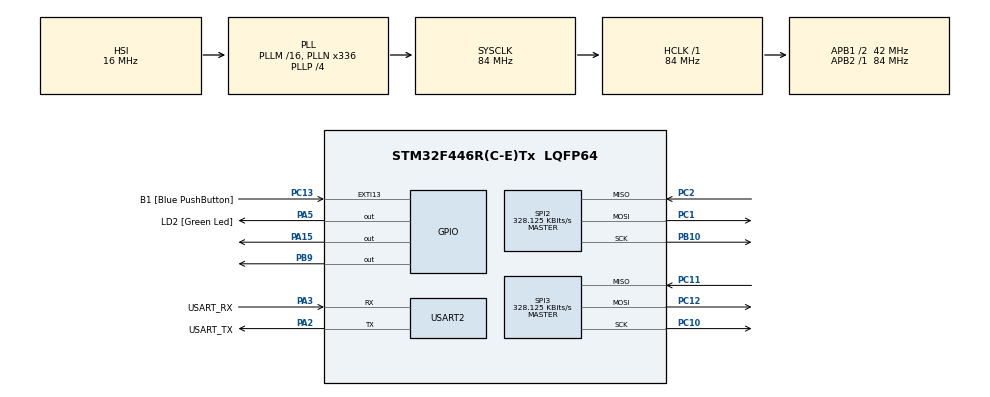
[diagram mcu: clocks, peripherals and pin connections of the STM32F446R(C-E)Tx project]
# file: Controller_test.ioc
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Mcu.Family=STM32F4
Mcu.Name=STM32F446R(C-E)Tx
Mcu.Package=LQFP64
NVIC.PriorityGroup=NVIC_PRIORITYGROUP_0
NVIC.TIM6_DAC_IRQn=true\:0\:0\:false\:false\:true\:true
PA13.GPIO_Label=TMS
PA13.Mode=Serial_Wire
PA13.Signal=SYS_JTMS-SWDIO
PA14.GPIO_Label=TCK
PA14.Mode=Serial_Wire
PA14.Signal=SYS_JTCK-SWCLK
PA15.Signal=GPIO_Output
PA2.GPIO_Label=USART_TX
PA2.Mode=Asynchronous
PA2.Signal=USART2_TX
PA3.GPIO_Label=USART_RX
PA3.Mode=Asynchronous
PA3.Signal=USART2_RX
PA5.GPIO_Label=LD2 [Green Led]
PA5.Signal=GPIO_Output
PB10.Mode=Full_Duplex_Master
PB10.Signal=SPI2_SCK
PB3.GPIO_Label=SWO
PB3.Signal=SYS_JTDO-SWO
PB9.Signal=GPIO_Output
PC1.Mode=Full_Duplex_Master
PC1.Signal=SPI2_MOSI
PC10.Mode=Full_Duplex_Master
PC10.Signal=SPI3_SCK
PC11.Mode=Full_Duplex_Master
PC11.Signal=SPI3_MISO
PC12.Mode=Full_Duplex_Master
PC12.Signal=SPI3_MOSI
PC13.GPIO_Label=B1 [Blue PushButton]
PC13.GPIO_ModeDefaultEXTI=GPIO_MODE_IT_FALLING
PC13.Signal=GPXTI13
PC14-OSC32_IN.Mode=LSE-External-Oscillator
PC14-OSC32_IN.Signal=RCC_OSC32_IN
PC15-OSC32_OUT.Mode=LSE-External-Oscillator
PC15-OSC32_OUT.Signal=RCC_OSC32_OUT
PC2.Mode=Full_Duplex_Master
PC2.Signal=SPI2_MISO
PH0-OSC_IN.Mode=HSE-External-Oscillator
PH0-OSC_IN.Signal=RCC_OSC_IN
PH1-OSC_OUT.Mode=HSE-External-Oscillator
PH1-OSC_OUT.Signal=RCC_OSC_OUT
ProjectManager.HeapSize=0x200
ProjectManager.StackSize=0x400
ProjectManager.TargetToolchain=SW4STM32
RCC.48MHZClocksFreq_Value=84000000
RCC.AHBFreq_Value=84000000
RCC.APB1CLKDivider=RCC_HCLK_DIV2
RCC.APB1Freq_Value=42000000
RCC.APB1TimFreq_Value=84000000
RCC.APB2Freq_Value=84000000
RCC.APB2TimFreq_Value=84000000
RCC.CortexFreq_Value=84000000
RCC.FLatency-AdvancedSettings=FLASH_LATENCY_2
RCC.HCLKFreq_Value=84000000
RCC.HSE_VALUE=8000000
RCC.HSI_VALUE=16000000
RCC.PLLN=336
RCC.PLLP=RCC_PLLP_DIV4
RCC.SYSCLKFreq_VALUE=84000000
RCC.SYSCLKSource=RCC_SYSCLKSOURCE_PLLCLK
RCC.USBFreq_Value=168000000
RCC.VCOOutputFreq_Value=336000000
SPI2.BaudRatePrescaler=SPI_BAUDRATEPRESCALER_128
SPI2.CLKPhase=SPI_PHASE_2EDGE
SPI2.CLKPolarity=SPI_POLARITY_HIGH
SPI2.CalculateBaudRate=328.125 KBits/s
SPI2.Direction=SPI_DIRECTION_2LINES
SPI2.FirstBit=SPI_FIRSTBIT_LSB
SPI2.Mode=SPI_MODE_MASTER
SPI2.VirtualType=VM_MASTER
SPI3.BaudRatePrescaler=SPI_BAUDRATEPRESCALER_128
SPI3.CLKPhase=SPI_PHASE_2EDGE
SPI3.CLKPolarity=SPI_POLARITY_HIGH
SPI3.CalculateBaudRate=328.125 KBits/s
SPI3.Direction=SPI_DIRECTION_2LINES
SPI3.FirstBit=SPI_FIRSTBIT_LSB
SPI3.Mode=SPI_MODE_MASTER
SPI3.VirtualType=VM_MASTER
TIM6.Period=32000
TIM6.Prescaler=999
USART2.VirtualMode=VM_ASYNC
VP_TIM6_VS_ClockSourceINT.Mode=Enable_Timer
board=NUCLEO-F446RE

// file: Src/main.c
/* USER CODE BEGIN Header */
/**
  ******************************************************************************
  * @file           : main.c
  * @brief          : Main program body
  ******************************************************************************
  ** This notice applies to any and all portions of this file
  * that are not between comment pairs USER CODE BEGIN and
  * USER CODE END. Other portions of this file, whether
  * inserted by the user or by software development tools
  * are owned by their respective copyright owners.
  *
  * COPYRIGHT(c) 2019 STMicroelectronics
  *
  * Redistribution and use in source and binary forms, with or without modification,
  * are permitted provided that the following conditions are met:
  *   1. Redistributions of source code must retain the above copyright notice,
  *      this list of conditions and the following disclaimer.
  *   2. Redistributions in binary form must reproduce the above copyright notice,
  *      this list of conditions and the following disclaimer in the documentation
  *      and/or other materials provided with the distribution.
  *   3. Neither the name of STMicroelectronics nor the names of its contributors
  *      may be used to endorse or promote products derived from this software
  *      without specific prior written permission.
  *
  * THIS SOFTWARE IS PROVIDED BY THE COPYRIGHT HOLDERS AND CONTRIBUTORS "AS IS"
  * AND ANY EXPRESS OR IMPLIED WARRANTIES, INCLUDING, BUT NOT LIMITED TO, THE
  * IMPLIED WARRANTIES OF MERCHANTABILITY AND FITNESS FOR A PARTICULAR PURPOSE ARE
  * DISCLAIMED. IN NO EVENT SHALL THE COPYRIGHT HOLDER OR CONTRIBUTORS BE LIABLE
  * FOR ANY DIRECT, INDIRECT, INCIDENTAL, SPECIAL, EXEMPLARY, OR CONSEQUENTIAL
  * DAMAGES (INCLUDING, BUT NOT LIMITED TO, PROCUREMENT OF SUBSTITUTE GOODS OR
  * SERVICES; LOSS OF USE, DATA, OR PROFITS; OR BUSINESS INTERRUPTION) HOWEVER
  * CAUSED AND ON ANY THEORY OF LIABILITY, WHETHER IN CONTRACT, STRICT LIABILITY,
  * OR TORT (INCLUDING NEGLIGENCE OR OTHERWISE) ARISING IN ANY WAY OUT OF THE USE
  * OF THIS SOFTWARE, EVEN IF ADVISED OF THE POSSIBILITY OF SUCH DAMAGE.
  *
  ******************************************************************************
  */
/* USER CODE END Header */

#include "main.h"
#include "struct.h"
#include "controller.h"
#include <stdlib.h>
#include "stm32f4xx_hal.h"

/* USER CODE BEGIN PM */
//#define CONTROLLER_SPI_HANDLER	hspi2
/* USER CODE END PM */

SPI_HandleTypeDef hspi2;
SPI_HandleTypeDef hspi3;

TIM_HandleTypeDef htim6;

UART_HandleTypeDef huart2;

/* USER CODE BEGIN PV */
static char s[255] = {'\0'};

/* USER CODE END PV */

void SystemClock_Config(void);
static void MX_GPIO_Init(void);
static void MX_USART2_UART_Init(void);
static void MX_TIM6_Init(void);
static void MX_SPI2_Init(void);
static void MX_SPI3_Init(void);

/* USER CODE BEGIN 0 */
void HAL_TIM_PeriodElapsedCallback(TIM_HandleTypeDef *htim){
	if(htim->Instance == TIM6){
		static uint16_t button_data = 0;

		PSControllerGetData(&button_data);
		//button_data = 0;
	    sprintf(s, "%d\r\n", (int)button_data);
	    HAL_UART_Transmit(&huart2,(uint8_t *)s, strlen(s), 100);
	}
}
/* USER CODE END 0 */

int main(void)
{

  /* MCU Configuration--------------------------------------------------------*/

  /* Reset of all peripherals, Initializes the Flash interface and the Systick. */
  HAL_Init();

  /* Configure the system clock */
  SystemClock_Config();

  /* Initialize all configured peripherals */
  MX_GPIO_Init();
  MX_USART2_UART_Init();
  MX_TIM6_Init();
  MX_SPI2_Init();
  MX_SPI3_Init();
  /* USER CODE BEGIN 2 */
  HAL_TIM_Base_Start_IT(&htim6);
  /* USER CODE END 2 */

  /* Infinite loop */
  while (1)
  {

  }
}

void SystemClock_Config(void)
{
  RCC_OscInitTypeDef RCC_OscInitStruct = {0};
  RCC_ClkInitTypeDef RCC_ClkInitStruct = {0};

  /**Configure the main internal regulator output voltage
  */
  __HAL_RCC_PWR_CLK_ENABLE();
  __HAL_PWR_VOLTAGESCALING_CONFIG(PWR_REGULATOR_VOLTAGE_SCALE3);
  /**Initializes the CPU, AHB and APB busses clocks
  */
  RCC_OscInitStruct.OscillatorType = RCC_OSCILLATORTYPE_HSI;
  RCC_OscInitStruct.HSIState = RCC_HSI_ON;
  RCC_OscInitStruct.HSICalibrationValue = RCC_HSICALIBRATION_DEFAULT;
  RCC_OscInitStruct.PLL.PLLState = RCC_PLL_ON;
  RCC_OscInitStruct.PLL.PLLSource = RCC_PLLSOURCE_HSI;
  RCC_OscInitStruct.PLL.PLLM = 16;
  RCC_OscInitStruct.PLL.PLLN = 336;
  RCC_OscInitStruct.PLL.PLLP = RCC_PLLP_DIV4;
  RCC_OscInitStruct.PLL.PLLQ = 2;
  RCC_OscInitStruct.PLL.PLLR = 2;
  if (HAL_RCC_OscConfig(&RCC_OscInitStruct) != HAL_OK)
  {
    Error_Handler();
  }
  /**Initializes the CPU, AHB and APB busses clocks
  */
  RCC_ClkInitStruct.ClockType = RCC_CLOCKTYPE_HCLK|RCC_CLOCKTYPE_SYSCLK
                              |RCC_CLOCKTYPE_PCLK1|RCC_CLOCKTYPE_PCLK2;
  RCC_ClkInitStruct.SYSCLKSource = RCC_SYSCLKSOURCE_PLLCLK;
  RCC_ClkInitStruct.AHBCLKDivider = RCC_SYSCLK_DIV1;
  RCC_ClkInitStruct.APB1CLKDivider = RCC_HCLK_DIV2;
  RCC_ClkInitStruct.APB2CLKDivider = RCC_HCLK_DIV1;

  if (HAL_RCC_ClockConfig(&RCC_ClkInitStruct, FLASH_LATENCY_2) != HAL_OK)
  {
    Error_Handler();
  }
}

static void MX_SPI2_Init(void)
{

  /* SPI2 parameter configuration*/
  hspi2.Instance = SPI2;
  hspi2.Init.Mode = SPI_MODE_MASTER;
  hspi2.Init.Direction = SPI_DIRECTION_2LINES;
  hspi2.Init.DataSize = SPI_DATASIZE_8BIT;
  hspi2.Init.CLKPolarity = SPI_POLARITY_HIGH;
  hspi2.Init.CLKPhase = SPI_PHASE_2EDGE;
  hspi2.Init.NSS = SPI_NSS_SOFT;
  hspi2.Init.BaudRatePrescaler = SPI_BAUDRATEPRESCALER_128;
  hspi2.Init.FirstBit = SPI_FIRSTBIT_LSB;
  hspi2.Init.TIMode = SPI_TIMODE_DISABLE;
  hspi2.Init.CRCCalculation = SPI_CRCCALCULATION_DISABLE;
  hspi2.Init.CRCPolynomial = 10;
  if (HAL_SPI_Init(&hspi2) != HAL_OK)
  {
    Error_Handler();
  }

}

static void MX_SPI3_Init(void)
{

  /* SPI3 parameter configuration*/
  hspi3.Instance = SPI3;
  hspi3.Init.Mode = SPI_MODE_MASTER;
  hspi3.Init.Direction = SPI_DIRECTION_2LINES;
  hspi3.Init.DataSize = SPI_DATASIZE_8BIT;
  hspi3.Init.CLKPolarity = SPI_POLARITY_HIGH;
  hspi3.Init.CLKPhase = SPI_PHASE_2EDGE;
  hspi3.Init.NSS = SPI_NSS_SOFT;
  hspi3.Init.BaudRatePrescaler = SPI_BAUDRATEPRESCALER_128;
  hspi3.Init.FirstBit = SPI_FIRSTBIT_LSB;
  hspi3.Init.TIMode = SPI_TIMODE_DISABLE;
  hspi3.Init.CRCCalculation = SPI_CRCCALCULATION_DISABLE;
  hspi3.Init.CRCPolynomial = 10;
  if (HAL_SPI_Init(&hspi3) != HAL_OK)
  {
    Error_Handler();
  }

}

static void MX_TIM6_Init(void)
{

  TIM_MasterConfigTypeDef sMasterConfig = {0};

  htim6.Instance = TIM6;
  htim6.Init.Prescaler = 999;
  htim6.Init.CounterMode = TIM_COUNTERMODE_UP;
  htim6.Init.Period = 32000;
  if (HAL_TIM_Base_Init(&htim6) != HAL_OK)
  {
    Error_Handler();
  }
  sMasterConfig.MasterOutputTrigger = TIM_TRGO_RESET;
  sMasterConfig.MasterSlaveMode = TIM_MASTERSLAVEMODE_DISABLE;
  if (HAL_TIMEx_MasterConfigSynchronization(&htim6, &sMasterConfig) != HAL_OK)
  {
    Error_Handler();
  }

}

static void MX_USART2_UART_Init(void)
{

  huart2.Instance = USART2;
  huart2.Init.BaudRate = 115200;
  huart2.Init.WordLength = UART_WORDLENGTH_8B;
  huart2.Init.StopBits = UART_STOPBITS_1;
  huart2.Init.Parity = UART_PARITY_NONE;
  huart2.Init.Mode = UART_MODE_TX_RX;
  huart2.Init.HwFlowCtl = UART_HWCONTROL_NONE;
  huart2.Init.OverSampling = UART_OVERSAMPLING_16;
  if (HAL_UART_Init(&huart2) != HAL_OK)
  {
    Error_Handler();
  }

}

static void MX_GPIO_Init(void)
{
  GPIO_InitTypeDef GPIO_InitStruct = {0};

  /* GPIO Ports Clock Enable */
  __HAL_RCC_GPIOC_CLK_ENABLE();
  __HAL_RCC_GPIOH_CLK_ENABLE();
  __HAL_RCC_GPIOA_CLK_ENABLE();
  __HAL_RCC_GPIOB_CLK_ENABLE();

  /*Configure GPIO pin Output Level */
  HAL_GPIO_WritePin(GPIOA, LD2_Pin|GPIO_PIN_15, GPIO_PIN_RESET);

  /*Configure GPIO pin Output Level */
  HAL_GPIO_WritePin(GPIOB, GPIO_PIN_9, GPIO_PIN_RESET);

  /*Configure GPIO pin : B1_Pin */
  GPIO_InitStruct.Pin = B1_Pin;
  GPIO_InitStruct.Mode = GPIO_MODE_IT_FALLING;
  GPIO_InitStruct.Pull = GPIO_NOPULL;
  HAL_GPIO_Init(B1_GPIO_Port, &GPIO_InitStruct);

  /*Configure GPIO pins : LD2_Pin PA15 */
  GPIO_InitStruct.Pin = LD2_Pin|GPIO_PIN_15;
  GPIO_InitStruct.Mode = GPIO_MODE_OUTPUT_PP;
  GPIO_InitStruct.Pull = GPIO_NOPULL;
  GPIO_InitStruct.Speed = GPIO_SPEED_FREQ_LOW;
  HAL_GPIO_Init(GPIOA, &GPIO_InitStruct);

  /*Configure GPIO pin : PB9 */
  GPIO_InitStruct.Pin = GPIO_PIN_9;
  GPIO_InitStruct.Mode = GPIO_MODE_OUTPUT_PP;
  GPIO_InitStruct.Pull = GPIO_NOPULL;
  GPIO_InitStruct.Speed = GPIO_SPEED_FREQ_LOW;
  HAL_GPIO_Init(GPIOB, &GPIO_InitStruct);

}

void Error_Handler(void)
{
}

/************************ (C) COPYRIGHT STMicroelectronics *****END OF FILE****/
